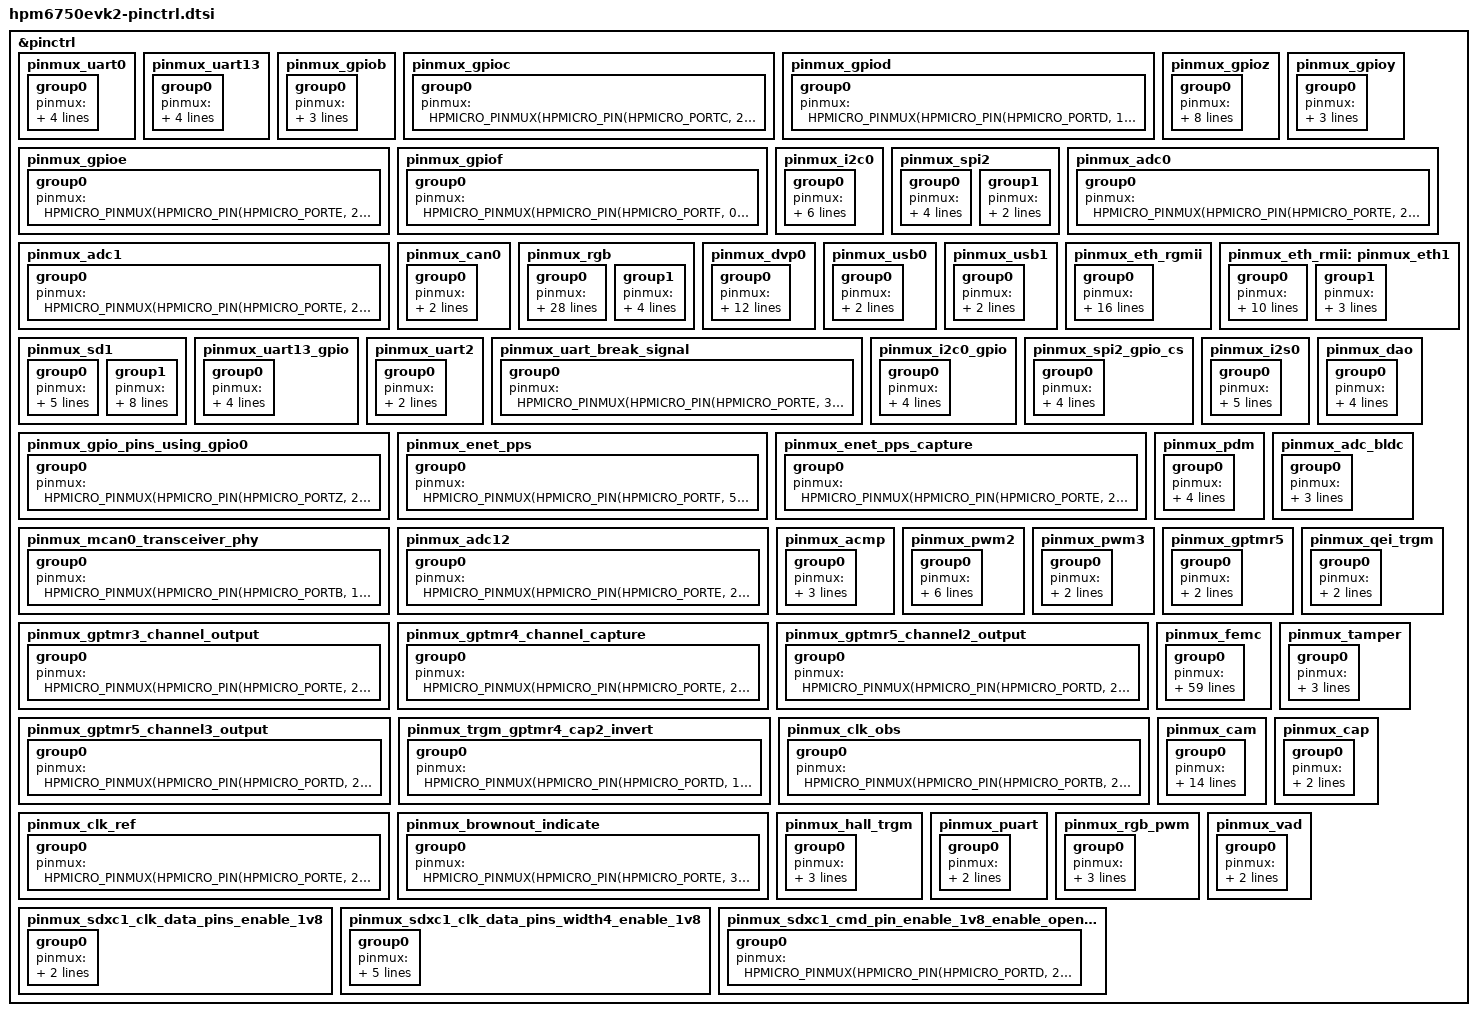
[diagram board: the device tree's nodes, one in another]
/*
* Copyright 2024-2026 HPMicro
* SPDX-License-Identifier: Apache-2.0
*/

#include "dt-bindings/pinctrl/hpmicro-pinctrl-common.h"

&pinctrl {
	pinmux_uart0: pinmux_uart0 {
		group0 {
			pinmux = <HPMICRO_PINMUX(HPMICRO_PIN(HPMICRO_PORTY, 7), IOC_TYPE_IOC, 0, 2)>,
				<HPMICRO_PINMUX(HPMICRO_PIN(HPMICRO_PORTY, 6), IOC_TYPE_IOC, 0, 2)>,
				<HPMICRO_PINMUX(HPMICRO_PIN(HPMICRO_PORTY, 7), IOC_TYPE_PIOC, 0, 3)>,
				<HPMICRO_PINMUX(HPMICRO_PIN(HPMICRO_PORTY, 6), IOC_TYPE_PIOC, 0, 3)>;
		};
	};

	pinmux_uart13: pinmux_uart13 {
		group0 {
			pinmux = <HPMICRO_PINMUX(HPMICRO_PIN(HPMICRO_PORTZ, 8), IOC_TYPE_IOC, 0, 2)>,
				<HPMICRO_PINMUX(HPMICRO_PIN(HPMICRO_PORTZ, 9), IOC_TYPE_IOC, 0, 2)>,
				<HPMICRO_PINMUX(HPMICRO_PIN(HPMICRO_PORTZ, 8), IOC_TYPE_BIOC, 0, 3)>,
				<HPMICRO_PINMUX(HPMICRO_PIN(HPMICRO_PORTZ, 9), IOC_TYPE_BIOC, 0, 3)>;
		};
	};

	pinmux_gpiob: pinmux_gpiob {
		group0 {
			pinmux =
				<HPMICRO_PINMUX(HPMICRO_PIN(HPMICRO_PORTB, 8), IOC_TYPE_IOC, 0, 0)>,
				<HPMICRO_PINMUX(HPMICRO_PIN(HPMICRO_PORTB, 9), IOC_TYPE_IOC, 0, 0)>;
			bias-pull-down;
		};
	};

	pinmux_gpioc: pinmux_gpioc {
		group0 {
			pinmux = <HPMICRO_PINMUX(HPMICRO_PIN(HPMICRO_PORTC, 20), IOC_TYPE_IOC, 0, 0)>;
		};
	};

	pinmux_gpiod: pinmux_gpiod {
		group0 {
			pinmux = <HPMICRO_PINMUX(HPMICRO_PIN(HPMICRO_PORTD, 15), IOC_TYPE_IOC, 0, 0)>;
		};
	};

	pinmux_gpioe: pinmux_gpioe {
		group0 {
			pinmux = <HPMICRO_PINMUX(HPMICRO_PIN(HPMICRO_PORTE, 31), IOC_TYPE_IOC, 0, 0)>;
			pinmux = <HPMICRO_PINMUX(HPMICRO_PIN(HPMICRO_PORTE, 26), IOC_TYPE_IOC, 0, 0)>;
		};
	};

	pinmux_gpiof: pinmux_gpiof {
		group0 {
			pinmux = <HPMICRO_PINMUX(HPMICRO_PIN(HPMICRO_PORTF, 0), IOC_TYPE_IOC, 0, 0)>;
		};
	};

	pinmux_gpioz: pinmux_gpioz {
		group0 {
			pinmux = <HPMICRO_PINMUX(HPMICRO_PIN(HPMICRO_PORTZ, 2), IOC_TYPE_IOC, 0, 0)>,
				<HPMICRO_PINMUX(HPMICRO_PIN(HPMICRO_PORTZ, 3), IOC_TYPE_IOC, 0, 0)>,
				<HPMICRO_PINMUX(HPMICRO_PIN(HPMICRO_PORTZ, 2), IOC_TYPE_BIOC, 0, 3)>,
				<HPMICRO_PINMUX(HPMICRO_PIN(HPMICRO_PORTZ, 3), IOC_TYPE_BIOC, 0, 3)>;
			bias-pull-up;
			input-enable;
			keeper-capability-disable;
			input-schmitt-enable;
		};
	};

	pinmux_gpioy: pinmux_gpioy {
		group0 {
			pinmux = <HPMICRO_PINMUX(HPMICRO_PIN(HPMICRO_PORTY, 5), IOC_TYPE_IOC, 0, 0)>,
				<HPMICRO_PINMUX(HPMICRO_PIN(HPMICRO_PORTY, 5), IOC_TYPE_BIOC, 0, 3)>;
			bias-pull-up;
		};
	};

	pinmux_i2c0: pinmux_i2c0 {
		group0 {
			pinmux = <HPMICRO_PINMUX(HPMICRO_PIN(HPMICRO_PORTZ, 10), IOC_TYPE_IOC, 0, 4)>,
				<HPMICRO_PINMUX(HPMICRO_PIN(HPMICRO_PORTZ, 11), IOC_TYPE_IOC, 0, 4)>,
				<HPMICRO_PINMUX(HPMICRO_PIN(HPMICRO_PORTZ, 10), IOC_TYPE_BIOC, 0, 3)>,
				<HPMICRO_PINMUX(HPMICRO_PIN(HPMICRO_PORTZ, 11), IOC_TYPE_BIOC, 0, 3)>;
			drive-open-drain;
			input-enable;
		};
	};

	pinmux_spi2: pinmux_spi2 {
		group0 {
			pinmux = <HPMICRO_PINMUX(HPMICRO_PIN(HPMICRO_PORTE, 27), IOC_TYPE_IOC, 0, 5)>,
				<HPMICRO_PINMUX(HPMICRO_PIN(HPMICRO_PORTE, 28), IOC_TYPE_IOC, 0, 5)>,
				<HPMICRO_PINMUX(HPMICRO_PIN(HPMICRO_PORTE, 30), IOC_TYPE_IOC, 0, 5)>;
			input-enable;
		};

		group1 {
			pinmux = <HPMICRO_PINMUX(HPMICRO_PIN(HPMICRO_PORTE, 31), IOC_TYPE_IOC, 0, 0)>;
			bias-pull-up;
		};
	};

	pinmux_adc0: pinmux_adc0 {
		group0 {
			pinmux = <HPMICRO_PINMUX(HPMICRO_PIN(HPMICRO_PORTE, 29), IOC_TYPE_IOC, 1, 0)>;
		};
	};

	pinmux_adc1: pinmux_adc1 {
		group0 {
			pinmux = <HPMICRO_PINMUX(HPMICRO_PIN(HPMICRO_PORTE, 21), IOC_TYPE_IOC, 1, 0)>;
		};
	};

	pinmux_can0: pinmux_can0 {
		group0 {
			pinmux = <HPMICRO_PINMUX(HPMICRO_PIN(HPMICRO_PORTB, 15), IOC_TYPE_IOC, 0, 7)>,
				<HPMICRO_PINMUX(HPMICRO_PIN(HPMICRO_PORTB, 17), IOC_TYPE_IOC, 0, 7)>;
		};
	};

	pinmux_rgb: pinmux_rgb {
		group0 {
			pinmux = <HPMICRO_PINMUX(HPMICRO_PIN(HPMICRO_PORTB, 3), IOC_TYPE_IOC, 0, 20)>,
				<HPMICRO_PINMUX(HPMICRO_PIN(HPMICRO_PORTB, 4), IOC_TYPE_IOC, 0, 20)>,
				<HPMICRO_PINMUX(HPMICRO_PIN(HPMICRO_PORTB, 0), IOC_TYPE_IOC, 0, 20)>,
				<HPMICRO_PINMUX(HPMICRO_PIN(HPMICRO_PORTA, 31), IOC_TYPE_IOC, 0, 20)>,
				<HPMICRO_PINMUX(HPMICRO_PIN(HPMICRO_PORTA, 26), IOC_TYPE_IOC, 0, 20)>,
				<HPMICRO_PINMUX(HPMICRO_PIN(HPMICRO_PORTA, 21), IOC_TYPE_IOC, 0, 20)>,
				<HPMICRO_PINMUX(HPMICRO_PIN(HPMICRO_PORTA, 27), IOC_TYPE_IOC, 0, 20)>,
				<HPMICRO_PINMUX(HPMICRO_PIN(HPMICRO_PORTA, 28), IOC_TYPE_IOC, 0, 20)>,
				<HPMICRO_PINMUX(HPMICRO_PIN(HPMICRO_PORTB, 6), IOC_TYPE_IOC, 0, 20)>,
				<HPMICRO_PINMUX(HPMICRO_PIN(HPMICRO_PORTB, 1), IOC_TYPE_IOC, 0, 20)>,
				<HPMICRO_PINMUX(HPMICRO_PIN(HPMICRO_PORTA, 22), IOC_TYPE_IOC, 0, 20)>,
				<HPMICRO_PINMUX(HPMICRO_PIN(HPMICRO_PORTA, 23), IOC_TYPE_IOC, 0, 20)>,
				<HPMICRO_PINMUX(HPMICRO_PIN(HPMICRO_PORTA, 29), IOC_TYPE_IOC, 0, 20)>,
				<HPMICRO_PINMUX(HPMICRO_PIN(HPMICRO_PORTA, 24), IOC_TYPE_IOC, 0, 20)>,
				<HPMICRO_PINMUX(HPMICRO_PIN(HPMICRO_PORTA, 30), IOC_TYPE_IOC, 0, 20)>,
				<HPMICRO_PINMUX(HPMICRO_PIN(HPMICRO_PORTA, 25), IOC_TYPE_IOC, 0, 20)>,
				<HPMICRO_PINMUX(HPMICRO_PIN(HPMICRO_PORTB, 5), IOC_TYPE_IOC, 0, 20)>,
				<HPMICRO_PINMUX(HPMICRO_PIN(HPMICRO_PORTB, 7), IOC_TYPE_IOC, 0, 20)>,
				<HPMICRO_PINMUX(HPMICRO_PIN(HPMICRO_PORTB, 2), IOC_TYPE_IOC, 0, 20)>,
				<HPMICRO_PINMUX(HPMICRO_PIN(HPMICRO_PORTA, 16), IOC_TYPE_IOC, 0, 20)>,
				<HPMICRO_PINMUX(HPMICRO_PIN(HPMICRO_PORTA, 12), IOC_TYPE_IOC, 0, 20)>,
				<HPMICRO_PINMUX(HPMICRO_PIN(HPMICRO_PORTA, 17), IOC_TYPE_IOC, 0, 20)>,
				<HPMICRO_PINMUX(HPMICRO_PIN(HPMICRO_PORTA, 13), IOC_TYPE_IOC, 0, 20)>,
				<HPMICRO_PINMUX(HPMICRO_PIN(HPMICRO_PORTA, 18), IOC_TYPE_IOC, 0, 20)>,
				<HPMICRO_PINMUX(HPMICRO_PIN(HPMICRO_PORTA, 20), IOC_TYPE_IOC, 0, 20)>,
				<HPMICRO_PINMUX(HPMICRO_PIN(HPMICRO_PORTA, 15), IOC_TYPE_IOC, 0, 20)>,
				<HPMICRO_PINMUX(HPMICRO_PIN(HPMICRO_PORTA, 19), IOC_TYPE_IOC, 0, 20)>,
				<HPMICRO_PINMUX(HPMICRO_PIN(HPMICRO_PORTA, 14), IOC_TYPE_IOC, 0, 20)>;
		};

		group1 {
			pinmux = <HPMICRO_PINMUX(HPMICRO_PIN(HPMICRO_PORTB, 16), IOC_TYPE_IOC, 0, 0)>,
				<HPMICRO_PINMUX(HPMICRO_PIN(HPMICRO_PORTB, 10), IOC_TYPE_IOC, 0, 0)>,
				<HPMICRO_PINMUX(HPMICRO_PIN(HPMICRO_PORTZ, 0), IOC_TYPE_IOC, 0, 0)>,
				<HPMICRO_PINMUX(HPMICRO_PIN(HPMICRO_PORTZ, 0), IOC_TYPE_BIOC, 0, 3)>;
		};
	};

	pinmux_dvp0: pinmux_dvp0 {
		group0 {
			pinmux = <HPMICRO_PINMUX(HPMICRO_PIN(HPMICRO_PORTA, 0), IOC_TYPE_IOC, 0, 22)>,
				<HPMICRO_PINMUX(HPMICRO_PIN(HPMICRO_PORTA, 1), IOC_TYPE_IOC, 0, 22)>,
				<HPMICRO_PINMUX(HPMICRO_PIN(HPMICRO_PORTA, 2), IOC_TYPE_IOC, 0, 22)>,
				<HPMICRO_PINMUX(HPMICRO_PIN(HPMICRO_PORTA, 3), IOC_TYPE_IOC, 0, 22)>,
				<HPMICRO_PINMUX(HPMICRO_PIN(HPMICRO_PORTA, 4), IOC_TYPE_IOC, 0, 22)>,
				<HPMICRO_PINMUX(HPMICRO_PIN(HPMICRO_PORTA, 5), IOC_TYPE_IOC, 0, 22)>,
				<HPMICRO_PINMUX(HPMICRO_PIN(HPMICRO_PORTA, 6), IOC_TYPE_IOC, 0, 22)>,
				<HPMICRO_PINMUX(HPMICRO_PIN(HPMICRO_PORTA, 7), IOC_TYPE_IOC, 0, 22)>,
				<HPMICRO_PINMUX(HPMICRO_PIN(HPMICRO_PORTA, 8), IOC_TYPE_IOC, 0, 22)>,
				<HPMICRO_PINMUX(HPMICRO_PIN(HPMICRO_PORTA, 9), IOC_TYPE_IOC, 0, 22)>,
				<HPMICRO_PINMUX(HPMICRO_PIN(HPMICRO_PORTA, 10), IOC_TYPE_IOC, 0, 22)>,
				<HPMICRO_PINMUX(HPMICRO_PIN(HPMICRO_PORTA, 11), IOC_TYPE_IOC, 0, 22)>;
		};
	};

	pinmux_usb0: pinmux_usb0 {
		group0 {
			pinmux = <HPMICRO_PINMUX(HPMICRO_PIN(HPMICRO_PORTF, 10), IOC_TYPE_IOC, 0, 24)>,
				<HPMICRO_PINMUX(HPMICRO_PIN(HPMICRO_PORTF,  8), IOC_TYPE_IOC, 0, 24)>;
		};
	};

	pinmux_usb1: pinmux_usb1 {
		group0 {
			pinmux = <HPMICRO_PINMUX(HPMICRO_PIN(HPMICRO_PORTF, 7), IOC_TYPE_IOC, 0, 24)>,
				<HPMICRO_PINMUX(HPMICRO_PIN(HPMICRO_PORTF, 5), IOC_TYPE_IOC, 0, 24)>;
		};
	};

	pinmux_eth_rgmii: pinmux_eth_rgmii {
		group0 {
			pinmux = <HPMICRO_PINMUX(HPMICRO_PIN(HPMICRO_PORTE, 22), IOC_TYPE_IOC, 0, 19)>,
				<HPMICRO_PINMUX(HPMICRO_PIN(HPMICRO_PORTE, 23), IOC_TYPE_IOC, 0, 19)>,
				<HPMICRO_PINMUX(HPMICRO_PIN(HPMICRO_PORTD, 31), IOC_TYPE_IOC, 0, 18)>,
				<HPMICRO_PINMUX(HPMICRO_PIN(HPMICRO_PORTE, 4), IOC_TYPE_IOC, 0, 18)>,
				<HPMICRO_PINMUX(HPMICRO_PIN(HPMICRO_PORTE, 2), IOC_TYPE_IOC, 0, 18)>,
				<HPMICRO_PINMUX(HPMICRO_PIN(HPMICRO_PORTE, 7), IOC_TYPE_IOC, 0, 18)>,
				<HPMICRO_PINMUX(HPMICRO_PIN(HPMICRO_PORTE, 3), IOC_TYPE_IOC, 0, 18)>,
				<HPMICRO_PINMUX(HPMICRO_PIN(HPMICRO_PORTD, 30), IOC_TYPE_IOC, 0, 18)>,
				<HPMICRO_PINMUX(HPMICRO_PIN(HPMICRO_PORTE, 6), IOC_TYPE_IOC, 0, 18)>,
				<HPMICRO_PINMUX(HPMICRO_PIN(HPMICRO_PORTD, 29), IOC_TYPE_IOC, 0, 18)>,
				<HPMICRO_PINMUX(HPMICRO_PIN(HPMICRO_PORTD, 28), IOC_TYPE_IOC, 0, 18)>,
				<HPMICRO_PINMUX(HPMICRO_PIN(HPMICRO_PORTE, 5), IOC_TYPE_IOC, 0, 18)>,
				<HPMICRO_PINMUX(HPMICRO_PIN(HPMICRO_PORTE, 1), IOC_TYPE_IOC, 0, 18)>,
				<HPMICRO_PINMUX(HPMICRO_PIN(HPMICRO_PORTE, 0), IOC_TYPE_IOC, 0, 18)>;
			input-schmitt-enable;
			drive-strength = "r000";
		};
	};

	pinmux_eth_rmii: pinmux_eth1 {
		group0 {
			pinmux = <HPMICRO_PINMUX(HPMICRO_PIN(HPMICRO_PORTD, 11), IOC_TYPE_IOC, 0, 19)>,
				<HPMICRO_PINMUX(HPMICRO_PIN(HPMICRO_PORTD, 14), IOC_TYPE_IOC, 0, 19)>,
				<HPMICRO_PINMUX(HPMICRO_PIN(HPMICRO_PORTE, 20), IOC_TYPE_IOC, 0, 18)>,
				<HPMICRO_PINMUX(HPMICRO_PIN(HPMICRO_PORTE, 18), IOC_TYPE_IOC, 0, 18)>,
				<HPMICRO_PINMUX(HPMICRO_PIN(HPMICRO_PORTE, 15), IOC_TYPE_IOC, 0, 18)>,
				<HPMICRO_PINMUX(HPMICRO_PIN(HPMICRO_PORTE, 19), IOC_TYPE_IOC, 0, 18)>,
				<HPMICRO_PINMUX(HPMICRO_PIN(HPMICRO_PORTE, 17), IOC_TYPE_IOC, 0, 18)>,
				<HPMICRO_PINMUX(HPMICRO_PIN(HPMICRO_PORTE, 14), IOC_TYPE_IOC, 0, 18)>;
			input-schmitt-enable;
			drive-strength = "r000";
		};

		group1 {
			pinmux = <HPMICRO_PINMUX(HPMICRO_PIN(HPMICRO_PORTE, 16), IOC_TYPE_IOC, 0, 18)>;
			input-schmitt-enable;
			input-enable;
		};
	};

	pinmux_sd1: pinmux_sd1 {
		group0 {
			pinmux = <HPMICRO_PINMUX(HPMICRO_PIN(HPMICRO_PORTD, 21), IOC_TYPE_IOC, 0, 17)>;
			bias-pull-up;
			input-enable;
			power-source = "3v3";
			drive-strength = "r110";
		};

		group1 {
			pinmux = <HPMICRO_PINMUX(HPMICRO_PIN(HPMICRO_PORTD, 22), IOC_TYPE_IOC, 0, 17)>,
				<HPMICRO_PINMUX(HPMICRO_PIN(HPMICRO_PORTD, 18), IOC_TYPE_IOC, 0, 17)>,
				<HPMICRO_PINMUX(HPMICRO_PIN(HPMICRO_PORTD, 17), IOC_TYPE_IOC, 0, 17)>,
				<HPMICRO_PINMUX(HPMICRO_PIN(HPMICRO_PORTD, 27), IOC_TYPE_IOC, 0, 17)>,
				<HPMICRO_PINMUX(HPMICRO_PIN(HPMICRO_PORTD, 26), IOC_TYPE_IOC, 0, 17)>;
			bias-pull-up;
			power-source = "3v3";
			drive-strength = "r110";
		};
	};

	pinmux_uart13_gpio: pinmux_uart13_gpio {
		group0 {
			pinmux = <HPMICRO_PINMUX(HPMICRO_PIN(HPMICRO_PORTZ, 8), IOC_TYPE_IOC, 0, 0)>,
				<HPMICRO_PINMUX(HPMICRO_PIN(HPMICRO_PORTZ, 8), IOC_TYPE_BIOC, 0, 3)>,
				<HPMICRO_PINMUX(HPMICRO_PIN(HPMICRO_PORTZ, 9), IOC_TYPE_IOC, 0, 0)>,
				<HPMICRO_PINMUX(HPMICRO_PIN(HPMICRO_PORTZ, 9), IOC_TYPE_BIOC, 0, 3)>;
		};
	};

	pinmux_uart2: pinmux_uart2 {
		group0 {
			pinmux = <HPMICRO_PINMUX(HPMICRO_PIN(HPMICRO_PORTE, 16), IOC_TYPE_IOC, 0, 2)>,
				<HPMICRO_PINMUX(HPMICRO_PIN(HPMICRO_PORTE, 21), IOC_TYPE_IOC, 0, 2)>;
		};
	};

	pinmux_uart_break_signal: pinmux_uart_break_signal {
		group0 {
			pinmux = <HPMICRO_PINMUX(HPMICRO_PIN(HPMICRO_PORTE, 31), IOC_TYPE_IOC, 0, 0)>;
		};
	};

	pinmux_i2c0_gpio: pinmux_i2c0_gpio {
		group0 {
			pinmux = <HPMICRO_PINMUX(HPMICRO_PIN(HPMICRO_PORTZ, 11), IOC_TYPE_IOC, 0, 0)>,
				<HPMICRO_PINMUX(HPMICRO_PIN(HPMICRO_PORTZ, 11), IOC_TYPE_BIOC, 0, 3)>,
				<HPMICRO_PINMUX(HPMICRO_PIN(HPMICRO_PORTZ, 10), IOC_TYPE_IOC, 0, 0)>,
				<HPMICRO_PINMUX(HPMICRO_PIN(HPMICRO_PORTZ, 10), IOC_TYPE_BIOC, 0, 3)>;
		};
	};

	pinmux_spi2_gpio_cs: pinmux_spi2_gpio_cs {
		group0 {
			pinmux = <HPMICRO_PINMUX(HPMICRO_PIN(HPMICRO_PORTE, 27), IOC_TYPE_IOC, 0, 5)>,
				<HPMICRO_PINMUX(HPMICRO_PIN(HPMICRO_PORTE, 28), IOC_TYPE_IOC, 0, 5)>,
				<HPMICRO_PINMUX(HPMICRO_PIN(HPMICRO_PORTE, 30), IOC_TYPE_IOC, 0, 5)>,
				<HPMICRO_PINMUX(HPMICRO_PIN(HPMICRO_PORTE, 31), IOC_TYPE_IOC, 0, 0)>;
		};
	};

	pinmux_gpio_pins_using_gpio0: pinmux_gpio_pins_using_gpio0 {
		group0 {
			pinmux =
				<HPMICRO_PINMUX(HPMICRO_PIN(HPMICRO_PORTZ, 2), IOC_TYPE_BIOC, 0, 3)>;
		};
	};

	pinmux_enet_pps: pinmux_enet_pps {
		group0 {
			pinmux = <HPMICRO_PINMUX(HPMICRO_PIN(HPMICRO_PORTF, 5), IOC_TYPE_IOC, 0, 19)>;
		};
	};

	pinmux_enet_pps_capture: pinmux_enet_pps_capture {
		group0 {
			pinmux = <HPMICRO_PINMUX(HPMICRO_PIN(HPMICRO_PORTE, 25), IOC_TYPE_IOC, 0, 19)>;
		};
	};

	pinmux_mcan0_transceiver_phy: pinmux_mcan0_transceiver_phy {
		group0 {
			pinmux = <HPMICRO_PINMUX(HPMICRO_PIN(HPMICRO_PORTB, 14), IOC_TYPE_IOC, 0, 0)>;
		};
	};

	pinmux_i2s0: pinmux_i2s0 {
		group0 {
			pinmux = <HPMICRO_PINMUX(HPMICRO_PIN(HPMICRO_PORTF, 2), IOC_TYPE_IOC, 0, 9)>,
				<HPMICRO_PINMUX(HPMICRO_PIN(HPMICRO_PORTF, 3), IOC_TYPE_IOC, 0, 9)>,
				<HPMICRO_PINMUX(HPMICRO_PIN(HPMICRO_PORTF, 4), IOC_TYPE_IOC, 0, 9)>,
				<HPMICRO_PINMUX(HPMICRO_PIN(HPMICRO_PORTF, 6), IOC_TYPE_IOC, 0, 9)>,
				<HPMICRO_PINMUX(HPMICRO_PIN(HPMICRO_PORTF, 9), IOC_TYPE_IOC, 0, 9)>;
		};
	};

	pinmux_dao: pinmux_dao {
		group0 {
			pinmux = <HPMICRO_PINMUX(HPMICRO_PIN(HPMICRO_PORTY, 8), IOC_TYPE_IOC, 0, 10)>,
				<HPMICRO_PINMUX(HPMICRO_PIN(HPMICRO_PORTY, 8), IOC_TYPE_PIOC, 0, 3)>,
				<HPMICRO_PINMUX(HPMICRO_PIN(HPMICRO_PORTY, 9), IOC_TYPE_IOC, 0, 10)>,
				<HPMICRO_PINMUX(HPMICRO_PIN(HPMICRO_PORTY, 9), IOC_TYPE_PIOC, 0, 3)>;
		};
	};

	pinmux_pdm: pinmux_pdm {
		group0 {
			pinmux = <HPMICRO_PINMUX(HPMICRO_PIN(HPMICRO_PORTY, 10), IOC_TYPE_IOC, 0, 10)>,
				<HPMICRO_PINMUX(HPMICRO_PIN(HPMICRO_PORTY, 10), IOC_TYPE_PIOC, 0, 3)>,
				<HPMICRO_PINMUX(HPMICRO_PIN(HPMICRO_PORTY, 11), IOC_TYPE_IOC, 0, 10)>,
				<HPMICRO_PINMUX(HPMICRO_PIN(HPMICRO_PORTY, 11), IOC_TYPE_PIOC, 0, 3)>;
		};
	};

	pinmux_adc12: pinmux_adc12 {
		group0 {
			pinmux = <HPMICRO_PINMUX(HPMICRO_PIN(HPMICRO_PORTE, 25), IOC_TYPE_IOC, 1, 0)>;
		};
	};

	pinmux_adc_bldc: pinmux_adc_bldc {
		group0 {
			pinmux = <HPMICRO_PINMUX(HPMICRO_PIN(HPMICRO_PORTE, 21), IOC_TYPE_IOC, 1, 0)>,
				<HPMICRO_PINMUX(HPMICRO_PIN(HPMICRO_PORTE, 24), IOC_TYPE_IOC, 1, 0)>,
				<HPMICRO_PINMUX(HPMICRO_PIN(HPMICRO_PORTE, 25), IOC_TYPE_IOC, 1, 0)>;
		};
	};

	pinmux_acmp: pinmux_acmp {
		group0 {
			pinmux = <HPMICRO_PINMUX(HPMICRO_PIN(HPMICRO_PORTE, 25), IOC_TYPE_IOC, 0, 16)>,
				<HPMICRO_PINMUX(HPMICRO_PIN(HPMICRO_PORTE, 23), IOC_TYPE_IOC, 1, 0)>,
				<HPMICRO_PINMUX(HPMICRO_PIN(HPMICRO_PORTE, 21), IOC_TYPE_IOC, 1, 0)>;
		};
	};

	pinmux_pwm2: pinmux_pwm2 {
		group0 {
			pinmux = <HPMICRO_PINMUX(HPMICRO_PIN(HPMICRO_PORTD, 28), IOC_TYPE_IOC, 0, 16)>,
				<HPMICRO_PINMUX(HPMICRO_PIN(HPMICRO_PORTD, 29), IOC_TYPE_IOC, 0, 16)>,
				<HPMICRO_PINMUX(HPMICRO_PIN(HPMICRO_PORTD, 30), IOC_TYPE_IOC, 0, 16)>,
				<HPMICRO_PINMUX(HPMICRO_PIN(HPMICRO_PORTD, 31), IOC_TYPE_IOC, 0, 16)>,
				<HPMICRO_PINMUX(HPMICRO_PIN(HPMICRO_PORTE, 3), IOC_TYPE_IOC, 0, 16)>,
				<HPMICRO_PINMUX(HPMICRO_PIN(HPMICRO_PORTE, 4), IOC_TYPE_IOC, 0, 16)>;
		};
	};

	pinmux_pwm3: pinmux_pwm3 {
		group0 {
			pinmux = <HPMICRO_PINMUX(HPMICRO_PIN(HPMICRO_PORTE, 17), IOC_TYPE_IOC, 0, 16)>,
				<HPMICRO_PINMUX(HPMICRO_PIN(HPMICRO_PORTE, 18), IOC_TYPE_IOC, 0, 16)>;
		};
	};

	pinmux_gptmr3_channel_output: pinmux_gptmr3_channel_output {
		group0 {
			pinmux = <HPMICRO_PINMUX(HPMICRO_PIN(HPMICRO_PORTE, 24), IOC_TYPE_IOC, 0, 1)>;
		};
	};

	pinmux_gptmr4_channel_capture: pinmux_gptmr4_channel_capture {
		group0 {
			pinmux = <HPMICRO_PINMUX(HPMICRO_PIN(HPMICRO_PORTE, 25), IOC_TYPE_IOC, 0, 1)>;
		};
	};

	pinmux_gptmr5: pinmux_gptmr5 {
		group0 {
			pinmux = <HPMICRO_PINMUX(HPMICRO_PIN(HPMICRO_PORTD, 24), IOC_TYPE_IOC, 0, 16)>,
				<HPMICRO_PINMUX(HPMICRO_PIN(HPMICRO_PORTD, 23), IOC_TYPE_IOC, 0, 16)>;
		};
	};

	pinmux_gptmr5_channel2_output: pinmux_gptmr5_channel2_output {
		group0 {
			pinmux = <HPMICRO_PINMUX(HPMICRO_PIN(HPMICRO_PORTD, 24), IOC_TYPE_IOC, 0, 16)>;
		};
	};

	pinmux_gptmr5_channel3_output: pinmux_gptmr5_channel3_output {
		group0 {
			pinmux = <HPMICRO_PINMUX(HPMICRO_PIN(HPMICRO_PORTD, 23), IOC_TYPE_IOC, 0, 16)>;
		};
	};

	pinmux_qei_trgm: pinmux_qei_trgm {
		group0 {
			pinmux = <HPMICRO_PINMUX(HPMICRO_PIN(HPMICRO_PORTD, 19), IOC_TYPE_IOC, 0, 16)>,
				<HPMICRO_PINMUX(HPMICRO_PIN(HPMICRO_PORTD, 24), IOC_TYPE_IOC, 0, 16)>;
		};
	};

	pinmux_trgm_gptmr4_cap2_invert: pinmux_trgm_gptmr4_cap2_invert {
		group0 {
			pinmux = <HPMICRO_PINMUX(HPMICRO_PIN(HPMICRO_PORTD, 16), IOC_TYPE_IOC, 0, 16)>;
		};
	};

	pinmux_femc: pinmux_femc {
		group0 {
			pinmux = <HPMICRO_PINMUX(HPMICRO_PIN(HPMICRO_PORTC, 1), IOC_TYPE_IOC, 0, 12)>,
				<HPMICRO_PINMUX(HPMICRO_PIN(HPMICRO_PORTC, 0), IOC_TYPE_IOC, 0, 12)>,
				<HPMICRO_PINMUX(HPMICRO_PIN(HPMICRO_PORTB, 31), IOC_TYPE_IOC, 0, 12)>,
				<HPMICRO_PINMUX(HPMICRO_PIN(HPMICRO_PORTB, 30), IOC_TYPE_IOC, 0, 12)>,
				<HPMICRO_PINMUX(HPMICRO_PIN(HPMICRO_PORTB, 29), IOC_TYPE_IOC, 0, 12)>,
				<HPMICRO_PINMUX(HPMICRO_PIN(HPMICRO_PORTB, 28), IOC_TYPE_IOC, 0, 12)>,
				<HPMICRO_PINMUX(HPMICRO_PIN(HPMICRO_PORTB, 27), IOC_TYPE_IOC, 0, 12)>,
				<HPMICRO_PINMUX(HPMICRO_PIN(HPMICRO_PORTB, 26), IOC_TYPE_IOC, 0, 12)>,
				<HPMICRO_PINMUX(HPMICRO_PIN(HPMICRO_PORTB, 25), IOC_TYPE_IOC, 0, 12)>,
				<HPMICRO_PINMUX(HPMICRO_PIN(HPMICRO_PORTB, 24), IOC_TYPE_IOC, 0, 12)>,
				<HPMICRO_PINMUX(HPMICRO_PIN(HPMICRO_PORTB, 23), IOC_TYPE_IOC, 0, 12)>,
				<HPMICRO_PINMUX(HPMICRO_PIN(HPMICRO_PORTB, 22), IOC_TYPE_IOC, 0, 12)>,
				<HPMICRO_PINMUX(HPMICRO_PIN(HPMICRO_PORTB, 21), IOC_TYPE_IOC, 0, 12)>,
				<HPMICRO_PINMUX(HPMICRO_PIN(HPMICRO_PORTB, 20), IOC_TYPE_IOC, 0, 12)>,
				<HPMICRO_PINMUX(HPMICRO_PIN(HPMICRO_PORTB, 19), IOC_TYPE_IOC, 0, 12)>,
				<HPMICRO_PINMUX(HPMICRO_PIN(HPMICRO_PORTB, 18), IOC_TYPE_IOC, 0, 12)>,
				<HPMICRO_PINMUX(HPMICRO_PIN(HPMICRO_PORTD, 13), IOC_TYPE_IOC, 0, 12)>,
				<HPMICRO_PINMUX(HPMICRO_PIN(HPMICRO_PORTD, 12), IOC_TYPE_IOC, 0, 12)>,
				<HPMICRO_PINMUX(HPMICRO_PIN(HPMICRO_PORTD, 10), IOC_TYPE_IOC, 0, 12)>,
				<HPMICRO_PINMUX(HPMICRO_PIN(HPMICRO_PORTD, 9), IOC_TYPE_IOC, 0, 12)>,
				<HPMICRO_PINMUX(HPMICRO_PIN(HPMICRO_PORTD, 8), IOC_TYPE_IOC, 0, 12)>,
				<HPMICRO_PINMUX(HPMICRO_PIN(HPMICRO_PORTD, 7), IOC_TYPE_IOC, 0, 12)>,
				<HPMICRO_PINMUX(HPMICRO_PIN(HPMICRO_PORTD, 6), IOC_TYPE_IOC, 0, 12)>,
				<HPMICRO_PINMUX(HPMICRO_PIN(HPMICRO_PORTD, 5), IOC_TYPE_IOC, 0, 12)>,
				<HPMICRO_PINMUX(HPMICRO_PIN(HPMICRO_PORTD, 4), IOC_TYPE_IOC, 0, 12)>,
				<HPMICRO_PINMUX(HPMICRO_PIN(HPMICRO_PORTD, 3), IOC_TYPE_IOC, 0, 12)>,
				<HPMICRO_PINMUX(HPMICRO_PIN(HPMICRO_PORTD, 2), IOC_TYPE_IOC, 0, 12)>,
				<HPMICRO_PINMUX(HPMICRO_PIN(HPMICRO_PORTD, 1), IOC_TYPE_IOC, 0, 12)>,
				<HPMICRO_PINMUX(HPMICRO_PIN(HPMICRO_PORTD, 0), IOC_TYPE_IOC, 0, 12)>,
				<HPMICRO_PINMUX(HPMICRO_PIN(HPMICRO_PORTC, 29), IOC_TYPE_IOC, 0, 12)>,
				<HPMICRO_PINMUX(HPMICRO_PIN(HPMICRO_PORTC, 28), IOC_TYPE_IOC, 0, 12)>,
				<HPMICRO_PINMUX(HPMICRO_PIN(HPMICRO_PORTC, 27), IOC_TYPE_IOC, 0, 12)>,
				<HPMICRO_PINMUX(HPMICRO_PIN(HPMICRO_PORTC, 21), IOC_TYPE_IOC, 0, 12)>,
				<HPMICRO_PINMUX(HPMICRO_PIN(HPMICRO_PORTC, 17), IOC_TYPE_IOC, 0, 12)>,
				<HPMICRO_PINMUX(HPMICRO_PIN(HPMICRO_PORTC, 15), IOC_TYPE_IOC, 0, 12)>,
				<HPMICRO_PINMUX(HPMICRO_PIN(HPMICRO_PORTC, 12), IOC_TYPE_IOC, 0, 12)>,
				<HPMICRO_PINMUX(HPMICRO_PIN(HPMICRO_PORTC, 11), IOC_TYPE_IOC, 0, 12)>,
				<HPMICRO_PINMUX(HPMICRO_PIN(HPMICRO_PORTC, 10), IOC_TYPE_IOC, 0, 12)>,
				<HPMICRO_PINMUX(HPMICRO_PIN(HPMICRO_PORTC, 9), IOC_TYPE_IOC, 0, 12)>,
				<HPMICRO_PINMUX(HPMICRO_PIN(HPMICRO_PORTC, 8), IOC_TYPE_IOC, 0, 12)>,
				<HPMICRO_PINMUX(HPMICRO_PIN(HPMICRO_PORTC, 7), IOC_TYPE_IOC, 0, 12)>,
				<HPMICRO_PINMUX(HPMICRO_PIN(HPMICRO_PORTC, 6), IOC_TYPE_IOC, 0, 12)>,
				<HPMICRO_PINMUX(HPMICRO_PIN(HPMICRO_PORTC, 5), IOC_TYPE_IOC, 0, 12)>,
				<HPMICRO_PINMUX(HPMICRO_PIN(HPMICRO_PORTC, 4), IOC_TYPE_IOC, 0, 12)>,
				<HPMICRO_PINMUX(HPMICRO_PIN(HPMICRO_PORTC, 14), IOC_TYPE_IOC, 0, 12)>,
				<HPMICRO_PINMUX(HPMICRO_PIN(HPMICRO_PORTC, 13), IOC_TYPE_IOC, 0, 12)>,
				<HPMICRO_PINMUX(HPMICRO_PIN(HPMICRO_PORTC, 16), IOC_TYPE_IOC, 0, 12)>,
				<HPMICRO_PINMUX(HPMICRO_PIN(HPMICRO_PORTC, 26), IOC_TYPE_IOC, 0, 12)>,
				<HPMICRO_PINMUX(HPMICRO_PIN(HPMICRO_PORTC, 25), IOC_TYPE_IOC, 0, 12)>,
				<HPMICRO_PINMUX(HPMICRO_PIN(HPMICRO_PORTC, 19), IOC_TYPE_IOC, 0, 12)>,
				<HPMICRO_PINMUX(HPMICRO_PIN(HPMICRO_PORTC, 18), IOC_TYPE_IOC, 0, 12)>,
				<HPMICRO_PINMUX(HPMICRO_PIN(HPMICRO_PORTC, 23), IOC_TYPE_IOC, 0, 12)>,
				<HPMICRO_PINMUX(HPMICRO_PIN(HPMICRO_PORTC, 24), IOC_TYPE_IOC, 0, 12)>,
				<HPMICRO_PINMUX(HPMICRO_PIN(HPMICRO_PORTC, 30), IOC_TYPE_IOC, 0, 12)>,
				<HPMICRO_PINMUX(HPMICRO_PIN(HPMICRO_PORTC, 31), IOC_TYPE_IOC, 0, 12)>,
				<HPMICRO_PINMUX(HPMICRO_PIN(HPMICRO_PORTC, 2), IOC_TYPE_IOC, 0, 12)>,
				<HPMICRO_PINMUX(HPMICRO_PIN(HPMICRO_PORTC, 3), IOC_TYPE_IOC, 0, 12)>,
				<HPMICRO_PINMUX(HPMICRO_PIN(HPMICRO_PORTC, 20), IOC_TYPE_IOC, 0, 12)>,
				<HPMICRO_PINMUX(HPMICRO_PIN(HPMICRO_PORTC, 22), IOC_TYPE_IOC, 0, 12)>;
		};
	};

	pinmux_tamper: pinmux_tamper {
		group0 {
			pinmux = <HPMICRO_PINMUX(HPMICRO_PIN(HPMICRO_PORTZ, 8), IOC_TYPE_BIOC, 0, 2)>,
				<HPMICRO_PINMUX(HPMICRO_PIN(HPMICRO_PORTZ, 9), IOC_TYPE_BIOC, 0, 2)>,
				<HPMICRO_PINMUX(HPMICRO_PIN(HPMICRO_PORTZ, 10), IOC_TYPE_BIOC, 0, 2)>;
		};
	};

	pinmux_clk_obs: pinmux_clk_obs {
		group0 {
			pinmux = <HPMICRO_PINMUX(HPMICRO_PIN(HPMICRO_PORTB, 2), IOC_TYPE_IOC, 0, 24)>;
		};
	};

	pinmux_clk_ref: pinmux_clk_ref {
		group0 {
			pinmux = <HPMICRO_PINMUX(HPMICRO_PIN(HPMICRO_PORTE, 24), IOC_TYPE_IOC, 0, 24)>;
		};
	};

	pinmux_brownout_indicate: pinmux_brownout_indicate {
		group0 {
			pinmux = <HPMICRO_PINMUX(HPMICRO_PIN(HPMICRO_PORTE, 30), IOC_TYPE_IOC, 0, 0)>;
		};
	};

	pinmux_cam: pinmux_cam {
		group0 {
			pinmux = <HPMICRO_PINMUX(HPMICRO_PIN(HPMICRO_PORTY, 5), IOC_TYPE_IOC, 0, 0)>,
				<HPMICRO_PINMUX(HPMICRO_PIN(HPMICRO_PORTY, 5), IOC_TYPE_PIOC, 0, 3)>,
				<HPMICRO_PINMUX(HPMICRO_PIN(HPMICRO_PORTA, 7), IOC_TYPE_IOC, 0, 22)>,
				<HPMICRO_PINMUX(HPMICRO_PIN(HPMICRO_PORTA, 3), IOC_TYPE_IOC, 0, 22)>,
				<HPMICRO_PINMUX(HPMICRO_PIN(HPMICRO_PORTA, 8), IOC_TYPE_IOC, 0, 22)>,
				<HPMICRO_PINMUX(HPMICRO_PIN(HPMICRO_PORTA, 9), IOC_TYPE_IOC, 0, 22)>,
				<HPMICRO_PINMUX(HPMICRO_PIN(HPMICRO_PORTA, 0), IOC_TYPE_IOC, 0, 22)>,
				<HPMICRO_PINMUX(HPMICRO_PIN(HPMICRO_PORTA, 4), IOC_TYPE_IOC, 0, 22)>,
				<HPMICRO_PINMUX(HPMICRO_PIN(HPMICRO_PORTA, 1), IOC_TYPE_IOC, 0, 22)>,
				<HPMICRO_PINMUX(HPMICRO_PIN(HPMICRO_PORTA, 2), IOC_TYPE_IOC, 0, 22)>,
				<HPMICRO_PINMUX(HPMICRO_PIN(HPMICRO_PORTA, 10), IOC_TYPE_IOC, 0, 22)>,
				<HPMICRO_PINMUX(HPMICRO_PIN(HPMICRO_PORTA, 5), IOC_TYPE_IOC, 0, 22)>,
				<HPMICRO_PINMUX(HPMICRO_PIN(HPMICRO_PORTA, 6), IOC_TYPE_IOC, 0, 22)>,
				<HPMICRO_PINMUX(HPMICRO_PIN(HPMICRO_PORTA, 11), IOC_TYPE_IOC, 0, 22)>;
		};
	};

	pinmux_cap: pinmux_cap {
		group0 {
			pinmux = <HPMICRO_PINMUX(HPMICRO_PIN(HPMICRO_PORTB, 8), IOC_TYPE_IOC, 0, 0)>,
				<HPMICRO_PINMUX(HPMICRO_PIN(HPMICRO_PORTB, 9), IOC_TYPE_IOC, 0, 0)>;
		};
	};

	pinmux_hall_trgm: pinmux_hall_trgm {
		group0 {
			pinmux = <HPMICRO_PINMUX(HPMICRO_PIN(HPMICRO_PORTD, 16), IOC_TYPE_IOC, 0, 16)>,
				<HPMICRO_PINMUX(HPMICRO_PIN(HPMICRO_PORTD, 20), IOC_TYPE_IOC, 0, 16)>,
				<HPMICRO_PINMUX(HPMICRO_PIN(HPMICRO_PORTD, 25), IOC_TYPE_IOC, 0, 16)>;
		};
	};

	pinmux_puart: pinmux_puart {
		group0 {
			pinmux = <HPMICRO_PINMUX(HPMICRO_PIN(HPMICRO_PORTY, 6), IOC_TYPE_PIOC, 0, 1)>,
				<HPMICRO_PINMUX(HPMICRO_PIN(HPMICRO_PORTY, 7), IOC_TYPE_PIOC, 0, 1)>;
		};
	};

	pinmux_rgb_pwm: pinmux_rgb_pwm {
		group0 {
			pinmux = <HPMICRO_PINMUX(HPMICRO_PIN(HPMICRO_PORTB, 11), IOC_TYPE_IOC, 0, 16)>,
				<HPMICRO_PINMUX(HPMICRO_PIN(HPMICRO_PORTB, 12), IOC_TYPE_IOC, 0, 16)>,
				<HPMICRO_PINMUX(HPMICRO_PIN(HPMICRO_PORTB, 13), IOC_TYPE_IOC, 0, 16)>;
		};
	};

	pinmux_sdxc1_clk_data_pins_enable_1v8: pinmux_sdxc1_clk_data_pins_enable_1v8 {
		group0 {
			pinmux = <HPMICRO_PINMUX(HPMICRO_PIN(HPMICRO_PORTD, 22), IOC_TYPE_IOC, 0, 17)>,
				<HPMICRO_PINMUX(HPMICRO_PIN(HPMICRO_PORTD, 18), IOC_TYPE_IOC, 0, 17)>;
		};
	};

	pinmux_sdxc1_clk_data_pins_width4_enable_1v8: pinmux_sdxc1_clk_data_pins_width4_enable_1v8 {
		group0 {
			pinmux = <HPMICRO_PINMUX(HPMICRO_PIN(HPMICRO_PORTD, 17), IOC_TYPE_IOC, 0, 17)>,
				<HPMICRO_PINMUX(HPMICRO_PIN(HPMICRO_PORTD, 27), IOC_TYPE_IOC, 0, 17)>,
				<HPMICRO_PINMUX(HPMICRO_PIN(HPMICRO_PORTD, 26), IOC_TYPE_IOC, 0, 17)>,
				<HPMICRO_PINMUX(HPMICRO_PIN(HPMICRO_PORTD, 22), IOC_TYPE_IOC, 0, 17)>,
				<HPMICRO_PINMUX(HPMICRO_PIN(HPMICRO_PORTD, 18), IOC_TYPE_IOC, 0, 17)>;
		};
	};

	pinmux_sdxc1_cmd_pin_enable_1v8_enable_opendrain: pinmux_sdxc1_cmd_pin_enable_1v8_enable_opendrain {
		group0 {
			pinmux = <HPMICRO_PINMUX(HPMICRO_PIN(HPMICRO_PORTD, 21), IOC_TYPE_IOC, 0, 17)>;
		};
	};

	pinmux_vad: pinmux_vad {
		group0 {
			pinmux = <HPMICRO_PINMUX(HPMICRO_PIN(HPMICRO_PORTY, 10), IOC_TYPE_PIOC, 0, 1)>,
				<HPMICRO_PINMUX(HPMICRO_PIN(HPMICRO_PORTY, 11), IOC_TYPE_PIOC, 0, 1)>;
		};
	};
};
